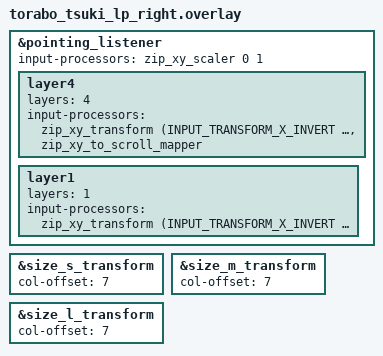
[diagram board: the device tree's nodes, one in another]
#include "torabo_tsuki_lp.dtsi"
#include <input/processors.dtsi>
#include <dt-bindings/zmk/input_transform.h>

&pointing_listener {
    input-processors = <&zip_xy_scaler 0 1>;

    layer4 {
        layers = <4>;
        input-processors = <&zip_xy_transform (INPUT_TRANSFORM_X_INVERT | INPUT_TRANSFORM_Y_INVERT) &zip_xy_to_scroll_mapper>;
    };
    layer1 {
        layers = <1>;
        input-processors = <&zip_xy_transform (INPUT_TRANSFORM_X_INVERT | INPUT_TRANSFORM_Y_INVERT)>;
    };
};

&size_s_transform {
    col-offset = <7>;
};

&size_m_transform {
    col-offset = <7>;
};

&size_l_transform {
    col-offset = <7>;
};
